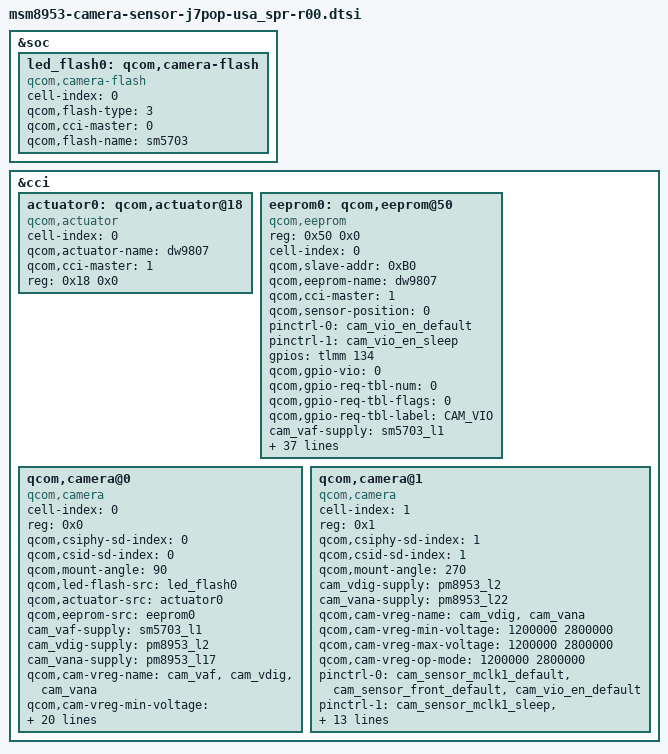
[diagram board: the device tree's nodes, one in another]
/*
 * Copyright (c) 2015, The Linux Foundation. All rights reserved.
 *
 * This program is free software; you can redistribute it and/or modify
 * it under the terms of the GNU General Public License version 2 and
 * only version 2 as published by the Free Software Foundation.
 *
 * This program is distributed in the hope that it will be useful,
 * but WITHOUT ANY WARRANTY; without even the implied warranty of
 * MERCHANTABILITY or FITNESS FOR A PARTICULAR PURPOSE.  See the
 * GNU General Public License for more details.
 */

&soc {
		led_flash0: qcom,camera-flash {
		cell-index = <0>;
		compatible = "qcom,camera-flash";
		qcom,flash-type = <3>;
		qcom,cci-master = <0>;
		qcom,flash-name = "sm5703";
	};
};

&cci {
	actuator0: qcom,actuator@18 {
		compatible = "qcom,actuator";
		cell-index = <0>;
		qcom,actuator-name = "dw9807";
		qcom,cci-master = <1>;
		reg = <0x18 0x0>;
	};


	eeprom0: qcom,eeprom@50 {
		compatible = "qcom,eeprom";
		reg = <0x50 0x0>;
		cell-index = <0>;
		qcom,slave-addr = <0xB0>;
		qcom,eeprom-name = "dw9807";
		qcom,cci-master = <1>;
		qcom,sensor-position = <0>;

		pinctrl-names = "cam_default", "cam_suspend";
		pinctrl-0 = <&cam_vio_en_default>;
		pinctrl-1 = <&cam_vio_en_sleep>;
		gpios = <&tlmm 134 0>;
		qcom,gpio-vio = <0>;
		qcom,gpio-req-tbl-num = <0>;
		qcom,gpio-req-tbl-flags = <0>;
		qcom,gpio-req-tbl-label = "CAM_VIO";

		cam_vaf-supply = <&sm5703_l1>;
		qcom,cam-vreg-name = "cam_vaf";
		qcom,cam-vreg-type = <0>;
		qcom,cam-vreg-min-voltage = <2800000>;
		qcom,cam-vreg-max-voltage = <2800000>;
		qcom,cam-vreg-op-mode = <100000>;
		qcom,cam-power-seq-type = "sensor_vreg", "sensor_gpio";
		qcom,cam-power-seq-val = "cam_vaf", "sensor_gpio_vio";
		qcom,cam-power-seq-cfg-val = <1 1>;
		qcom,cam-power-seq-delay = <2 10>;

		qcom,num-blocks = <8>;
		qcom,page0 = <0 0 0 0 0 0>;
		qcom,poll0 = <0 0 0 0 0 0>;
		qcom,mem0 = <0xBF 0x00 2 0 1 0>;
		qcom,page1 = <0 0 0 0 0 0>;
		qcom,poll1 = <0 0 0 0 0 0>;
		qcom,mem1 = <0x4 0xFC 2 0 1 0>;
		qcom,page2 = <0 0 0 0 0 0>;
		qcom,poll2 = <0 0 0 0 0 0>;
		qcom,mem2 = <0x7B0 0x100 2 0 1 0>;
		qcom,page3 = <0 0 0 0 0 0>;
		qcom,poll3 = <0 0 0 0 0 0>;
		qcom,mem3 = <0x4 0x8FC 2 0 1 0>;
		qcom,page4 = <0 0 0 0 0 0>;
		qcom,poll4 = <0 0 0 0 0 0>;
		qcom,mem4 = <0x20 0x900 2 0 1 0>;
		qcom,page5 = <0 0 0 0 0 0>;
		qcom,poll5 = <0 0 0 0 0 0>;
		qcom,mem5 = <0x4 0x9FC 2 0 1 0>;
		qcom,page6 = <0 0 0 0 0 0>;
		qcom,poll6 = <0 0 0 0 0 0>;
		qcom,mem6 = <0x700 0xA00 2 0 1 0>;
		qcom,page7 = <0 0 0 0 0 0>;
		qcom,poll7 = <0 0 0 0 0 0>;
		qcom,mem7 = <0x4 0x11FC 2 0 1 0>;
		qcom,total-size = <0x1200>;
	};


	qcom,camera@0 {
		cell-index = <0>;
		compatible = "qcom,camera";
		reg = <0x0>;
		qcom,csiphy-sd-index = <0>;
		qcom,csid-sd-index = <0>;
		qcom,mount-angle = <90>;
		qcom,led-flash-src = <&led_flash0>;
		qcom,actuator-src = <&actuator0>;
		qcom,eeprom-src = <&eeprom0>;

		cam_vaf-supply = <&sm5703_l1>;
		cam_vdig-supply = <&pm8953_l2>;
		cam_vana-supply = <&pm8953_l17>;
		qcom,cam-vreg-name = "cam_vaf","cam_vdig","cam_vana";
		qcom,cam-vreg-min-voltage = <2800000 1200000 2800000> ;
		qcom,cam-vreg-max-voltage = <2800000 1200000 2800000>;
		qcom,cam-vreg-op-mode = <2800000 1200000 2800000>;

		pinctrl-names = "cam_default", "cam_suspend";
		pinctrl-0 = <&cam_sensor_mclk0_default &cam_sensor_rear_default &cam_vio_en_default>;
		pinctrl-1 = <&cam_sensor_mclk0_sleep &cam_sensor_rear_sleep &cam_vio_en_sleep>;
		gpios = <&tlmm 26 0>,
			<&tlmm 40 0>,			
			<&tlmm 134 0>;
		qcom,gpio-reset = <1>;
		qcom,gpio-vio = <2>;
		qcom,gpio-req-tbl-num = <0 1 2>;
		qcom,gpio-req-tbl-flags = <1 0 0>;
		qcom,gpio-req-tbl-label = "CAMIF_MCLK0",
			"CAM_RESET0",
			"CAM_VIO";
		qcom,sensor-position = <0>;
		qcom,sensor-mode = <0>;
		qcom,cci-master = <0>;
		status = "ok";
		clocks = <&clock_gcc clk_mclk0_clk_src>,
				<&clock_gcc clk_gcc_camss_mclk0_clk>;
		clock-names = "cam_src_clk", "cam_clk";
	};


	qcom,camera@1 {
		cell-index = <1>;
		compatible = "qcom,camera";
		reg = <0x1>;
		qcom,csiphy-sd-index = <1>;
		qcom,csid-sd-index = <1>;
		qcom,mount-angle = <270>;
				
		cam_vdig-supply = <&pm8953_l2>;
		cam_vana-supply = <&pm8953_l22>;
		qcom,cam-vreg-name = "cam_vdig","cam_vana";
		qcom,cam-vreg-min-voltage = <1200000 2800000> ;
		qcom,cam-vreg-max-voltage = <1200000 2800000>;
		qcom,cam-vreg-op-mode = <1200000 2800000>;

		pinctrl-names = "cam_default", "cam_suspend";
		pinctrl-0 = <&cam_sensor_mclk1_default &cam_sensor_front_default &cam_vio_en_default>;
		pinctrl-1 = <&cam_sensor_mclk1_sleep &cam_sensor_front_sleep &cam_vio_en_sleep>;
		gpios = <&tlmm 27 0>,
			<&tlmm 129 0>,
			<&tlmm 134 0>;
		qcom,gpio-reset = <1>;
		qcom,gpio-vio = <2>;
		qcom,gpio-req-tbl-num = <0 1 2>;
		qcom,gpio-req-tbl-flags = <1 0 0>;
		qcom,gpio-req-tbl-label = "CAMIF_MCLK1",
			"CAM_RESET1",
  	  		"CAM_VIO";
		qcom,sensor-position = <1>;
		qcom,sensor-mode = <0>;
		qcom,cci-master = <0>;
		status = "ok";
		clocks = <&clock_gcc clk_mclk1_clk_src>,
				<&clock_gcc clk_gcc_camss_mclk1_clk>;
		clock-names = "cam_src_clk", "cam_clk";
	};	
};
